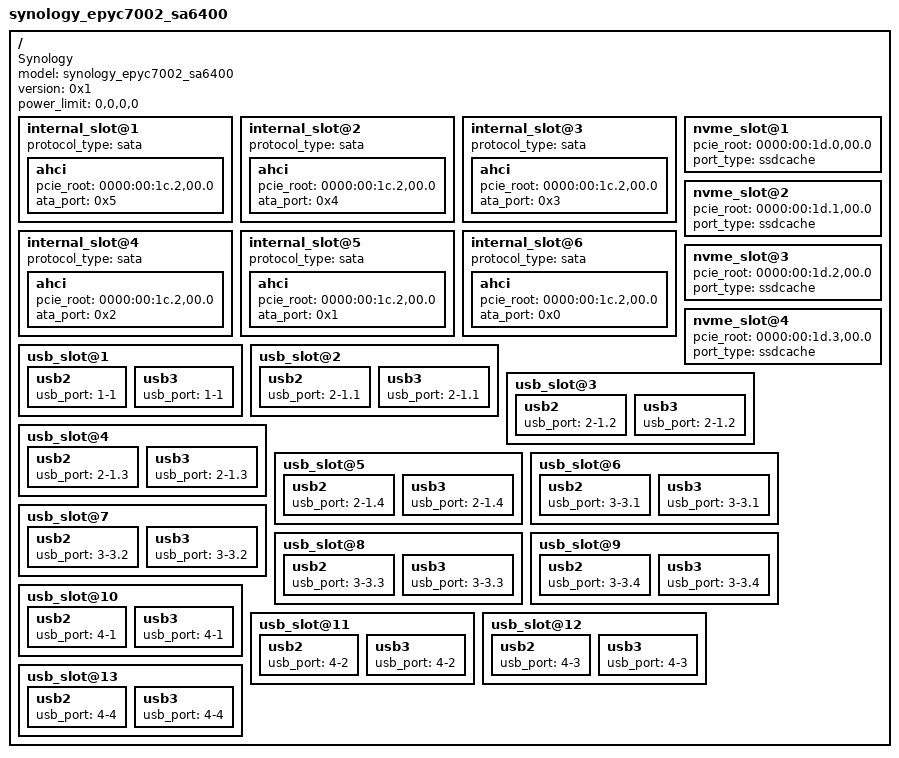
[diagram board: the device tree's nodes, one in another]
/dts-v1/;
// version: 17
// last_comp_version: 16
// boot_cpuid_phys: 0x0

/ {
    compatible = "Synology";
    model = "synology_epyc7002_sa6400";
    version = <0x1>;
    power_limit = "0,0,0,0";
    internal_slot@1 {
        protocol_type = "sata";
        ahci {
            pcie_root = "0000:00:1c.2,00.0";
            ata_port = <0x5>;
        };
    };
    internal_slot@2 {
        protocol_type = "sata";
        ahci {
            pcie_root = "0000:00:1c.2,00.0";
            ata_port = <0x4>;
        };
    };
    internal_slot@3 {
        protocol_type = "sata";
        ahci {
            pcie_root = "0000:00:1c.2,00.0";
            ata_port = <0x3>;
        };
    };
    internal_slot@4 {
        protocol_type = "sata";
        ahci {
            pcie_root = "0000:00:1c.2,00.0";
            ata_port = <0x2>;
        };
    };
    internal_slot@5 {
        protocol_type = "sata";
        ahci {
            pcie_root = "0000:00:1c.2,00.0";
            ata_port = <0x1>;
        };
    };
    internal_slot@6 {
        protocol_type = "sata";
        ahci {
            pcie_root = "0000:00:1c.2,00.0";
            ata_port = <0x0>;
        };
    };
    nvme_slot@1 {
        pcie_root = "0000:00:1d.0,00.0";
        port_type = "ssdcache";
    };
    nvme_slot@2 {
        pcie_root = "0000:00:1d.1,00.0";
        port_type = "ssdcache";
    };
    nvme_slot@3 {
        pcie_root = "0000:00:1d.2,00.0";
        port_type = "ssdcache";
    };
    nvme_slot@4 {
        pcie_root = "0000:00:1d.3,00.0";
        port_type = "ssdcache";
    };
    usb_slot@1 {
        usb2 {
            usb_port = "1-1";
        };
        usb3 {
            usb_port = "1-1";
        };
    };
    usb_slot@2 {
        usb2 {
            usb_port = "2-1.1";
        };
        usb3 {
            usb_port = "2-1.1";
        };
    };
    usb_slot@3 {
        usb2 {
            usb_port = "2-1.2";
        };
        usb3 {
            usb_port = "2-1.2";
        };
    };
    usb_slot@4 {
        usb2 {
            usb_port = "2-1.3";
        };
        usb3 {
            usb_port = "2-1.3";
        };
    };
    usb_slot@5 {
        usb2 {
            usb_port = "2-1.4";
        };
        usb3 {
            usb_port = "2-1.4";
        };
    };
    usb_slot@6 {
        usb2 {
            usb_port = "3-3.1";
        };
        usb3 {
            usb_port = "3-3.1";
        };
    };
    usb_slot@7 {
        usb2 {
            usb_port = "3-3.2";
        };
        usb3 {
            usb_port = "3-3.2";
        };
    };
    usb_slot@8 {
        usb2 {
            usb_port = "3-3.3";
        };
        usb3 {
            usb_port = "3-3.3";
        };
    };
    usb_slot@9 {
        usb2 {
            usb_port = "3-3.4";
        };
        usb3 {
            usb_port = "3-3.4";
        };
    };
    usb_slot@10 {
        usb2 {
            usb_port = "4-1";
        };
        usb3 {
            usb_port = "4-1";
        };
    };
    usb_slot@11 {
        usb2 {
            usb_port = "4-2";
        };
        usb3 {
            usb_port = "4-2";
        };
    };
    usb_slot@12 {
        usb2 {
            usb_port = "4-3";
        };
        usb3 {
            usb_port = "4-3";
        };
    };
    usb_slot@13 {
        usb2 {
            usb_port = "4-4";
        };
        usb3 {
            usb_port = "4-4";
        };
    };
};
